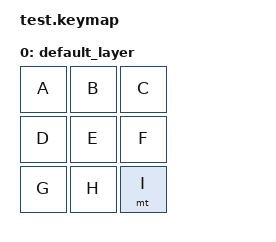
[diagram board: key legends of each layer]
// kbd3x3.keymap
#include <behaviors.dtsi>
#include <dt-bindings/zmk/keys.h>

 / {
    behaviors{
        mt: mod_tap {
            compatible = "zmk,behavior-hold-tap";
            #binding-cells = <2>;
            flavor = "hold-preferred";
            tapping-term-ms = <200>;
            bindings = <&kp>, <&bootloader>;
        };
    };

    keymap {
        compatible = "zmk,keymap";

        default_layer {
            bindings = <
                &kp A    &kp B    &kp C
                &kp D    &kp E    &kp F
                &kp G    &kp H    &mt I
            >;
        };
    };
};
